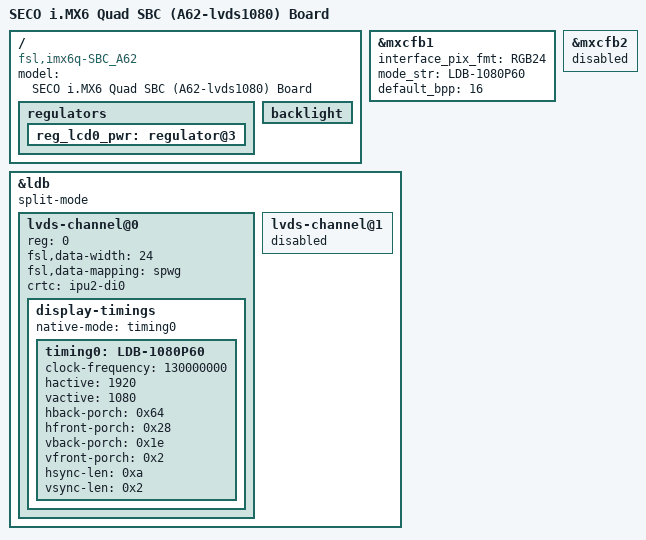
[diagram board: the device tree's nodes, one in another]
/*
 * Copyright 2013 Freescale Semiconductor, Inc.
 * Copyright 2015 Aidilab, Srl.
 *
 * The code contained herein is licensed under the GNU General Public
 * License. You may obtain a copy of the GNU General Public License
 * Version 2 or later at the following locations:
 *
 * http://www.opensource.org/licenses/gpl-license.html
 * http://www.gnu.org/copyleft/gpl.html
 */

/dts-v1/;

#include "imx6q.dtsi"
#include "imx6qdl-seco_A62.dtsi"

/ {
	model = "SECO i.MX6 Quad SBC (A62-lvds1080) Board";
	compatible = "fsl,imx6q-SBC_A62", "fsl,imx6q";

	regulators {
		reg_lcd0_pwr: regulator@3 {
			status = "okay";
		};
	};
	
	backlight {
		status = "okay";
	};
};

&mxcfb1 {
	interface_pix_fmt = "RGB24";
	mode_str ="LDB-1080P60";
	default_bpp = <16>;
	status = "okay";
};

&mxcfb2 {
	status = "disabled";
};


//		primary;
&ldb {
	status = "okay";
	split-mode;
	lvds-channel@0 {     
		reg = <0>;
		fsl,data-width = <24>;
		fsl,data-mapping = "spwg";
		crtc = "ipu2-di0";
		status = "okay";
		display-timings {
			native-mode = <&timing0>;
			timing0: LDB-1080P60 {
				clock-frequency = <130000000>;
				hactive = <1920>;
				vactive = <1080>;
				hback-porch = <0x64>;
				hfront-porch = <0x28>;
				vback-porch = <0x1e>;
				vfront-porch = <0x2>;
				hsync-len = <0xa>;
				vsync-len = <0x2>;
			};
		};
	};

	lvds-channel@1 {
		status = "disabled";
	};
};
